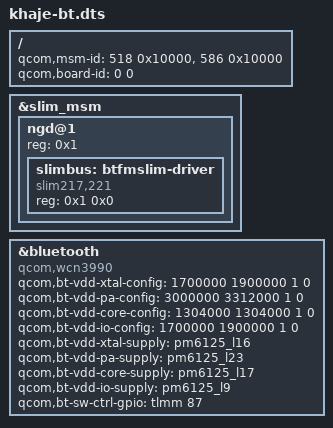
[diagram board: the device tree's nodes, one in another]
// SPDX-License-Identifier: GPL-2.0-only
/*
 * khaje Bluetooth (WCN3990 / btfm slimbus) base overlay
 *
 * Reconstructed from the stock Redmi Note 13 4G (sapphire) vendor_boot DTB
 * (HyperOS OS2.0.215.0.VNHEUXM): the Qualcomm "bt-devicetree" techpack
 * devicetree is not published, so this overlay was rebuilt from the nodes
 * and properties it contributes to the merged khaje base DTB.  It is applied
 * onto qcom/khaje.dtb with fdtoverlay, as kernel_platform merge_dtbs.py does.
 */

/dts-v1/;
/plugin/;


/ {
	qcom,msm-id = <518 0x10000>, <586 0x10000>;
	qcom,board-id = <0 0>;
};

&slim_msm {
	status = "ok";
	ngd@1 {
		#size-cells = <1>;
		#address-cells = <1>;
		reg = <0x1>;
		slimbus: btfmslim-driver {
			compatible = "slim217,221";
			reg = <0x1 0x0>;
		};
	};
};

&bluetooth {
	qcom,bt-vdd-xtal-config = <1700000 1900000 1 0>;
	qcom,bt-vdd-pa-config = <3000000 3312000 1 0>;
	qcom,bt-vdd-core-config = <1304000 1304000 1 0>;
	qcom,bt-vdd-io-config = <1700000 1900000 1 0>;
	qcom,bt-vdd-xtal-supply = <&pm6125_l16>;
	qcom,bt-vdd-pa-supply = <&pm6125_l23>;
	qcom,bt-vdd-core-supply = <&pm6125_l17>;
	qcom,bt-vdd-io-supply = <&pm6125_l9>;
	qcom,bt-sw-ctrl-gpio = <&tlmm 87 0>;
	compatible = "qcom,wcn3990";
};
